# TEST_BANK_PARTIAL: IP-XACT component
VLNV your.company:your.library:TEST_BANK_PARTIAL:1.0

## Address spaces and blocks
TEST_BANK.TEST_BANK: base 0x0, range 0x100, width 32

## Registers
Registers are 32-bit, read-write, reset 0x0 unless marked. A register's access mark holds for its fields unless they carry their own. Offsets are from the block's base; lines under a group give offsets from that group; [hi:lo] are bit positions; {n}, {i} and the like mark numbered series; 'fields as' and 'values as' point back to an identical list; <NAME> marks a mode.

## TEST_BANK.TEST_BANK
Base 0x00000000
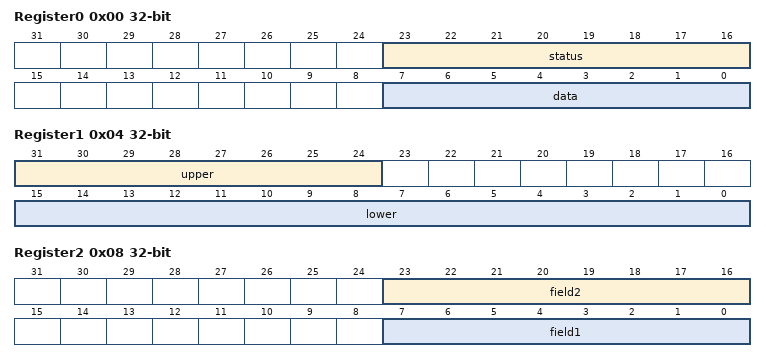
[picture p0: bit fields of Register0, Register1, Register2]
0x00 Register0
  [23:16] status, [7:0] data
0x04 Register1 ro
  [31:24] upper, [15:0] lower
0x08 Register2
  [23:16] field2, [7:0] field1
0x0C Register3 wo
  [31:0] reg3_field0
